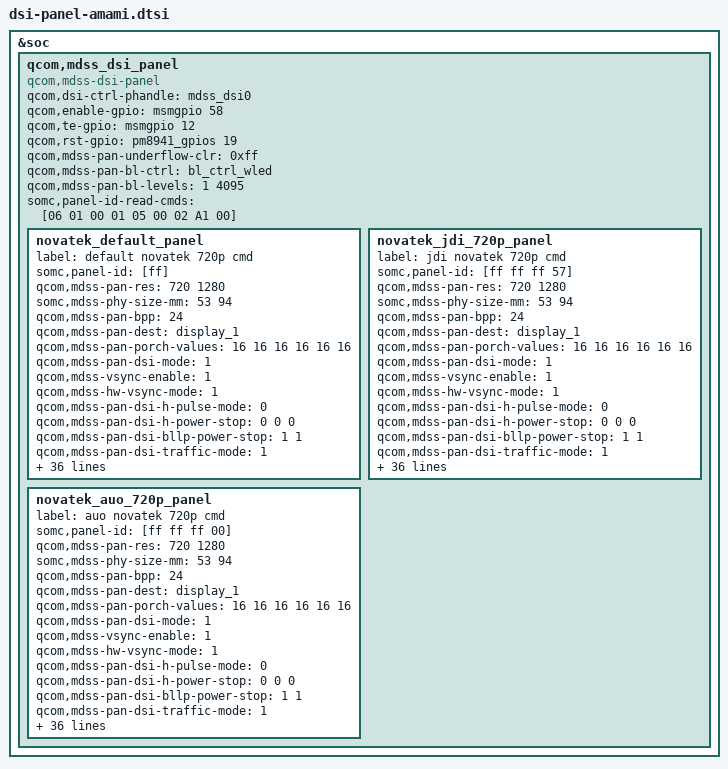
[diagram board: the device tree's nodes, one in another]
/* Copyright (c) 2012, Code Aurora Forum. All rights reserved.
 * Copyright (C) 2013 Sony Mobile Communications AB.
 *
 * This program is free software; you can redistribute it and/or modify
 * it under the terms of the GNU General Public License version 2 and
 * only version 2 as published by the Free Software Foundation.
 *
 * This program is distributed in the hope that it will be useful,
 * but WITHOUT ANY WARRANTY; without even the implied warranty of
 * MERCHANTABILITY or FITNESS FOR A PARTICULAR PURPOSE.  See the
 * GNU General Public License for more details.
 */

&soc {

	qcom,mdss_dsi_panel {
		/* common */
		compatible = "qcom,mdss-dsi-panel";
		status = "ok";
		qcom,dsi-ctrl-phandle = <&mdss_dsi0>;
		qcom,enable-gpio = <&msmgpio 58 0>;
		qcom,te-gpio = <&msmgpio 12 0>;
		qcom,rst-gpio = <&pm8941_gpios 19 0>;
		qcom,mdss-pan-underflow-clr = <0xff>;
		qcom,mdss-pan-bl-ctrl = "bl_ctrl_wled";
		qcom,mdss-pan-bl-levels = <1 4095>;
		somc,panel-id-read-cmds = [06 01 00 01 05 00 02 A1 00];

		novatek_default_panel {
			label = "default novatek 720p cmd";
			somc,panel-id = [ff];
			qcom,mdss-pan-res = <720 1280>;
			somc,mdss-phy-size-mm = <53 94>;
			qcom,mdss-pan-bpp = <24>;
			qcom,mdss-pan-dest = "display_1";
			qcom,mdss-pan-porch-values = <16 16 16 16 16 16>;
			qcom,mdss-pan-dsi-mode = <1>;
			qcom,mdss-vsync-enable = <1>;
			qcom,mdss-hw-vsync-mode = <1>;
			qcom,mdss-pan-dsi-h-pulse-mode = <0>;
			qcom,mdss-pan-dsi-h-power-stop = <0 0 0>;
			qcom,mdss-pan-dsi-bllp-power-stop = <1 1>;
			qcom,mdss-pan-dsi-traffic-mode = <1>;
			qcom,mdss-pan-dsi-dst-format = <8>;
			qcom,mdss-pan-insert-dcs-cmd = <1>;
			qcom,mdss-pan-wr-mem-continue = <0x3c>;
			qcom,mdss-pan-wr-mem-start = <0x2c>;
			qcom,mdss-pan-te-sel = <1>;
			qcom,mdss-pan-dsi-vc = <0>;
			qcom,mdss-pan-dsi-rgb-swap = <0>;
			qcom,mdss-pan-dsi-data-lanes = <1 1 1 1>;
			qcom,mdss-pan-dsi-dlane-swap = <0>;
			qcom,mdss-pan-dsi-t-clk = <0x18 0x05>;
			qcom,mdss-pan-dsi-stream = <0>;
			qcom,mdss-pan-dsi-mdp-tr = <0x0>;
			qcom,mdss-pan-dsi-dma-tr = <0x04>;
			qcom,mdss-pan-dsi-frame-rate = <60>;
			qcom,mdss-pan-clk-rate = <367170000>;
			qcom,panel-phy-regulatorSettings = [03 01 01 00  /* Regualotor settings */
							    20 00 01];
			qcom,panel-phy-timingSettings = [6f 18 0e 00 38 3e
						    12 1a 13 03 04 00];
			qcom,panel-phy-strengthCtrl = [77 06];
			qcom,panel-phy-bistCtrl = [00 00 b1 ff           /* BIST Ctrl settings */
						   00 00];
			qcom,panel-phy-laneConfig = [00 c2 45 00 00 00 00 01 75 /* lane0 config */
						00 c2 45 00 00 00 00 01 75 /* lane1 config */
						00 c2 45 00 00 00 00 01 75 /* lane2 config */
						00 c2 45 00 00 00 00 01 75 /* lane3 config */
						00 02 45 00 00 00 00 01 97]; /* Clk ln config */

			somc,panel-early-init-cmds = [15 01 00 00 00 00 02 FF EE
						15 01 00 00 01 00 02 26 08
						15 01 00 00 00 00 02 26 00
						15 01 00 00 00 00 02 FF 00];
			somc,panel-init-cmds = [15 01 00 00 00 00 02 BA 03
						15 01 00 00 00 00 02 C2 08
						15 01 00 00 00 00 02 FB 01
						15 01 00 00 00 00 02 FF EE
						15 01 00 00 00 00 02 12 50
						15 01 00 00 00 00 02 13 02
						15 01 00 00 00 00 02 6A 60
						15 01 00 00 00 00 02 FB 01
						15 01 00 00 00 00 02 FF 00
						15 01 00 00 0A 00 02 35 00
						05 01 00 00 00 00 01 11];
			qcom,panel-on-cmds = [05 01 00 00 00 00 01 29];
			qcom,on-cmds-dsi-state = "DSI_HS_MODE";
			qcom,panel-off-cmds = [05 01 00 00 00 00 01 28
					05 01 00 00 78 00 01 10];
			qcom,off-cmds-dsi-state = "DSI_HS_MODE";
			somc,driver-ic = <2>;
			somc,disp-on-in-hs = <0>;
			somc,panel-detect = <1>;
			somc,init-from-begin = <1>;
		};

		novatek_jdi_720p_panel {
			label = "jdi novatek 720p cmd";
			somc,panel-id = [ff ff ff 57];
			qcom,mdss-pan-res = <720 1280>;
			somc,mdss-phy-size-mm = <53 94>;
			qcom,mdss-pan-bpp = <24>;
			qcom,mdss-pan-dest = "display_1";
			qcom,mdss-pan-porch-values = <16 16 16 16 16 16>;
			qcom,mdss-pan-dsi-mode = <1>;
			qcom,mdss-vsync-enable = <1>;
			qcom,mdss-hw-vsync-mode = <1>;
			qcom,mdss-pan-dsi-h-pulse-mode = <0>;
			qcom,mdss-pan-dsi-h-power-stop = <0 0 0>;
			qcom,mdss-pan-dsi-bllp-power-stop = <1 1>;
			qcom,mdss-pan-dsi-traffic-mode = <1>;
			qcom,mdss-pan-dsi-dst-format = <8>;
			qcom,mdss-pan-insert-dcs-cmd = <1>;
			qcom,mdss-pan-wr-mem-continue = <0x3c>;
			qcom,mdss-pan-wr-mem-start = <0x2c>;
			qcom,mdss-pan-te-sel = <1>;
			qcom,mdss-pan-dsi-vc = <0>;
			qcom,mdss-pan-dsi-rgb-swap = <0>;
			qcom,mdss-pan-dsi-data-lanes = <1 1 1 1>;
			qcom,mdss-pan-dsi-dlane-swap = <0>;
			qcom,mdss-pan-dsi-t-clk = <0x18 0x05>;
			qcom,mdss-pan-dsi-stream = <0>;
			qcom,mdss-pan-dsi-mdp-tr = <0x0>;
			qcom,mdss-pan-dsi-dma-tr = <0x04>;
			qcom,mdss-pan-dsi-frame-rate = <60>;
			qcom,mdss-pan-clk-rate = <367170000>;
			qcom,panel-phy-regulatorSettings = [03 01 01 00  /* Regualotor settings */
							    20 00 01];
			qcom,panel-phy-timingSettings = [6f 18 0e 00 38 3e
						    12 1a 13 03 04 00];
			qcom,panel-phy-strengthCtrl = [77 06];
			qcom,panel-phy-bistCtrl = [00 00 b1 ff           /* BIST Ctrl settings */
						   00 00];
			qcom,panel-phy-laneConfig = [00 c2 45 00 00 00 00 01 75 /* lane0 config */
						00 c2 45 00 00 00 00 01 75 /* lane1 config */
						00 c2 45 00 00 00 00 01 75 /* lane2 config */
						00 c2 45 00 00 00 00 01 75 /* lane3 config */
						00 02 45 00 00 00 00 01 97]; /* Clk ln config */

			somc,panel-early-init-cmds = [15 01 00 00 00 00 02 FF EE
						15 01 00 00 01 00 02 26 08
						15 01 00 00 00 00 02 26 00
						15 01 00 00 00 00 02 FF 00];
			somc,panel-init-cmds = [15 01 00 00 00 00 02 BA 03
						15 01 00 00 00 00 02 C2 08
						15 01 00 00 00 00 02 FB 01
						15 01 00 00 00 00 02 FF EE
						15 01 00 00 00 00 02 12 50
						15 01 00 00 00 00 02 13 02
						15 01 00 00 00 00 02 6A 60
						15 01 00 00 00 00 02 FB 01
						15 01 00 00 00 00 02 FF 00
						15 01 00 00 0A 00 02 35 00
						05 01 00 00 00 00 01 11];
			qcom,panel-on-cmds = [05 01 00 00 00 00 01 29];
			qcom,on-cmds-dsi-state = "DSI_HS_MODE";
			qcom,panel-off-cmds = [05 01 00 00 00 00 01 28
					05 01 00 00 78 00 01 10];
			qcom,off-cmds-dsi-state = "DSI_HS_MODE";
			somc,driver-ic = <2>;
			somc,disp-on-in-hs = <0>;
			somc,panel-detect = <1>;
			somc,init-from-begin = <1>;
		};

		novatek_auo_720p_panel {
			label = "auo novatek 720p cmd";
			somc,panel-id = [ff ff ff 00];
			qcom,mdss-pan-res = <720 1280>;
			somc,mdss-phy-size-mm = <53 94>;
			qcom,mdss-pan-bpp = <24>;
			qcom,mdss-pan-dest = "display_1";
			qcom,mdss-pan-porch-values = <16 16 16 16 16 16>;
			qcom,mdss-pan-dsi-mode = <1>;
			qcom,mdss-vsync-enable = <1>;
			qcom,mdss-hw-vsync-mode = <1>;
			qcom,mdss-pan-dsi-h-pulse-mode = <0>;
			qcom,mdss-pan-dsi-h-power-stop = <0 0 0>;
			qcom,mdss-pan-dsi-bllp-power-stop = <1 1>;
			qcom,mdss-pan-dsi-traffic-mode = <1>;
			qcom,mdss-pan-dsi-dst-format = <8>;
			qcom,mdss-pan-insert-dcs-cmd = <1>;
			qcom,mdss-pan-wr-mem-continue = <0x3c>;
			qcom,mdss-pan-wr-mem-start = <0x2c>;
			qcom,mdss-pan-te-sel = <1>;
			qcom,mdss-pan-dsi-vc = <0>;
			qcom,mdss-pan-dsi-rgb-swap = <0>;
			qcom,mdss-pan-dsi-data-lanes = <1 1 1 1>;
			qcom,mdss-pan-dsi-dlane-swap = <0>;
			qcom,mdss-pan-dsi-t-clk = <0x18 0x05>;
			qcom,mdss-pan-dsi-stream = <0>;
			qcom,mdss-pan-dsi-mdp-tr = <0x0>;
			qcom,mdss-pan-dsi-dma-tr = <0x04>;
			qcom,mdss-pan-dsi-frame-rate = <60>;
			qcom,mdss-pan-clk-rate = <367170000>;
			qcom,panel-phy-regulatorSettings = [03 01 01 00  /* Regualotor settings */
							    20 00 01];
			qcom,panel-phy-timingSettings = [6f 18 0e 00 38 3e
						    12 1a 13 03 04 00];
			qcom,panel-phy-strengthCtrl = [77 06];
			qcom,panel-phy-bistCtrl = [00 00 b1 ff           /* BIST Ctrl settings */
						   00 00];
			qcom,panel-phy-laneConfig = [00 c2 45 00 00 00 00 01 75 /* lane0 config */
						00 c2 45 00 00 00 00 01 75 /* lane1 config */
						00 c2 45 00 00 00 00 01 75 /* lane2 config */
						00 c2 45 00 00 00 00 01 75 /* lane3 config */
						00 02 45 00 00 00 00 01 97]; /* Clk ln config */

			somc,panel-early-init-cmds = [15 01 00 00 00 00 02 FF EE
						15 01 00 00 01 00 02 26 08
						15 01 00 00 00 00 02 26 00
						15 01 00 00 00 00 02 FF 00];
			somc,panel-init-cmds = [15 01 00 00 00 00 02 FF EE
						15 01 00 00 00 00 02 FB 01
						15 01 00 00 00 00 02 12 50
						15 01 00 00 00 00 02 13 02
						15 01 00 00 00 00 02 FF 00
						15 01 00 00 00 00 02 FF 01
						15 01 00 00 00 00 02 FB 01
						15 01 00 00 00 00 02 00 4A
						15 01 00 00 00 00 02 01 43
						15 01 00 00 00 00 02 02 54
						15 01 00 00 00 00 02 03 55
						15 01 00 00 00 00 02 04 55
						15 01 00 00 00 00 02 05 33
						15 01 00 00 00 00 02 06 22
						15 01 00 00 00 00 02 08 56
						15 01 00 00 00 00 02 09 8F
						15 01 00 00 00 00 02 0B 97
						15 01 00 00 00 00 02 0C 97
						15 01 00 00 00 00 02 0D 2F
						15 01 00 00 00 00 02 0E 24
						15 01 00 00 00 00 02 36 73
						15 01 00 00 00 00 02 0F 04
						15 01 00 00 00 00 02 69 99
						15 01 00 00 00 00 02 6F 03
						15 01 00 00 00 00 02 FF 05
						15 01 00 00 00 00 02 FB 01
						15 01 00 00 00 00 02 01 00
						15 01 00 00 00 00 02 02 8D
						15 01 00 00 00 00 02 03 8D
						15 01 00 00 00 00 02 04 8D
						15 01 00 00 00 00 02 05 30
						15 01 00 00 00 00 02 06 33
						15 01 00 00 00 00 02 07 01
						15 01 00 00 00 00 02 08 00
						15 01 00 00 00 00 02 09 46
						15 01 00 00 00 00 02 0A 46
						15 01 00 00 00 00 02 0D 0B
						15 01 00 00 00 00 02 0E 1D
						15 01 00 00 00 00 02 0F 08
						15 01 00 00 00 00 02 10 53
						15 01 00 00 00 00 02 11 00
						15 01 00 00 00 00 02 12 00
						15 01 00 00 00 00 02 14 01
						15 01 00 00 00 00 02 15 00
						15 01 00 00 00 00 02 16 05
						15 01 00 00 00 00 02 17 04
						15 01 00 00 00 00 02 19 7F
						15 01 00 00 00 00 02 1A FF
						15 01 00 00 00 00 02 1B 0F
						15 01 00 00 00 00 02 1C 00
						15 01 00 00 00 00 02 1D 00
						15 01 00 00 00 00 02 1E 00
						15 01 00 00 00 00 02 1F 07
						15 01 00 00 00 00 02 20 00
						15 01 00 00 00 00 02 21 00
						15 01 00 00 00 00 02 22 55
						15 01 00 00 00 00 02 23 4D
						15 01 00 00 00 00 02 6C 00
						15 01 00 00 00 00 02 6D 00
						15 01 00 00 00 00 02 2D 02
						15 01 00 00 00 00 02 83 02
						15 01 00 00 00 00 02 9E 58
						15 01 00 00 00 00 02 9F 58
						15 01 00 00 00 00 02 A0 41
						15 01 00 00 00 00 02 A2 10
						15 01 00 00 00 00 02 BB 0A
						15 01 00 00 00 00 02 BC 0A
						15 01 00 00 00 00 02 28 01
						15 01 00 00 00 00 02 2F 02
						15 01 00 00 00 00 02 32 08
						15 01 00 00 00 00 02 33 B8
						15 01 00 00 00 00 02 36 02
						15 01 00 00 00 00 02 37 00
						15 01 00 00 00 00 02 43 00
						15 01 00 00 00 00 02 4B 21
						15 01 00 00 00 00 02 4C 03
						15 01 00 00 00 00 02 50 21
						15 01 00 00 00 00 02 51 03
						15 01 00 00 00 00 02 58 21
						15 01 00 00 00 00 02 59 03
						15 01 00 00 00 00 02 5D 21
						15 01 00 00 00 00 02 5E 03
						15 01 00 00 00 00 02 FF 00
						15 01 00 00 00 00 02 FB 01
						15 01 00 00 00 00 02 C2 08
						15 01 00 00 00 00 02 BA 03
						15 01 00 00 0A 00 02 35 00
						05 01 00 00 32 00 01 11];
			qcom,panel-on-cmds = [05 01 00 00 00 00 01 29];
			qcom,on-cmds-dsi-state = "DSI_HS_MODE";
			qcom,panel-off-cmds = [05 01 00 00 00 00 01 28
					05 01 00 00 78 00 01 10];
			qcom,off-cmds-dsi-state = "DSI_HS_MODE";
			somc,driver-ic = <2>;
			somc,disp-on-in-hs = <0>;
			somc,panel-detect = <1>;
			somc,init-from-begin = <1>;
		};

	};
};
